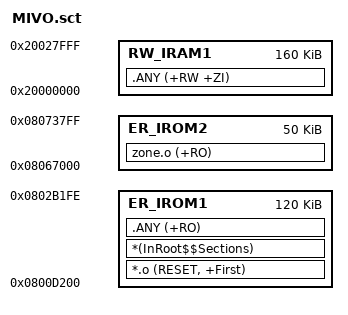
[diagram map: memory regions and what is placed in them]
; *************************************************************
; *** Scatter-Loading Description File generated by uVision ***
; *************************************************************
          
LR_IROM1 0x0800D200 0x1DFFF  {    ; load region size_region
  ER_IROM1 0x0800D200 0x1DFFF {  ; load address = execution address
   *.o (RESET, +First)
   *(InRoot$$Sections)
   .ANY (+RO)
  }
  RW_IRAM1 0x20000000 0x28000  {  ; RW data
   .ANY (+RW +ZI)
  }
}


LR_IROM2 0x08067000 0xC800  ; Zone List - ZoneList Size (100k) 
{
	ER_IROM2 0x08067000 0xC800
	{  
		zone.o  (+RO)
  }
}
